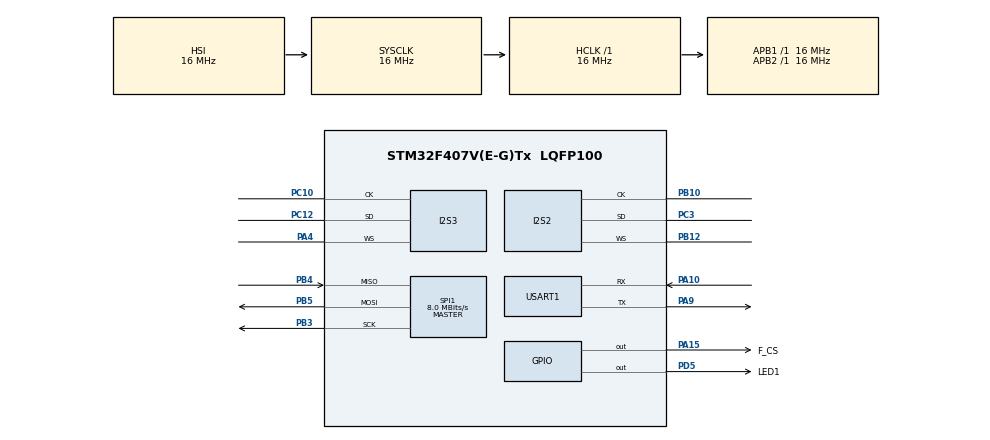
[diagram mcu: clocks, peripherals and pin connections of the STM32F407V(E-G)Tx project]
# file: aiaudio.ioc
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Dma.Request0=SPI2_RX
Dma.Request1=SPI3_TX
Dma.SPI2_RX.0.Direction=DMA_PERIPH_TO_MEMORY
Dma.SPI2_RX.0.FIFOMode=DMA_FIFOMODE_DISABLE
Dma.SPI2_RX.0.Instance=DMA1_Stream3
Dma.SPI2_RX.0.MemDataAlignment=DMA_MDATAALIGN_WORD
Dma.SPI2_RX.0.MemInc=DMA_MINC_ENABLE
Dma.SPI2_RX.0.Mode=DMA_CIRCULAR
Dma.SPI2_RX.0.PeriphDataAlignment=DMA_PDATAALIGN_WORD
Dma.SPI2_RX.0.PeriphInc=DMA_PINC_DISABLE
Dma.SPI2_RX.0.Priority=DMA_PRIORITY_LOW
Dma.SPI3_TX.1.Direction=DMA_MEMORY_TO_PERIPH
Dma.SPI3_TX.1.FIFOMode=DMA_FIFOMODE_DISABLE
Dma.SPI3_TX.1.Instance=DMA1_Stream5
Dma.SPI3_TX.1.MemDataAlignment=DMA_MDATAALIGN_HALFWORD
Dma.SPI3_TX.1.MemInc=DMA_MINC_ENABLE
Dma.SPI3_TX.1.Mode=DMA_CIRCULAR
Dma.SPI3_TX.1.PeriphDataAlignment=DMA_PDATAALIGN_HALFWORD
Dma.SPI3_TX.1.PeriphInc=DMA_PINC_DISABLE
Dma.SPI3_TX.1.Priority=DMA_PRIORITY_LOW
FREERTOS.Tasks01=defaultTask,24,128,StartDefaultTask,Default,NULL,Dynamic,NULL,NULL
I2S2.AudioFreq=I2S_AUDIOFREQ_16K
I2S2.DataFormat=I2S_DATAFORMAT_24B
I2S2.ErrorAudioFreq=0.0 %
I2S2.FullDuplexMode=I2S_FULLDUPLEXMODE_DISABLE
I2S2.Instance=SPI$Index
I2S2.Mode=I2S_MODE_MASTER_RX
I2S2.RealAudioFreq=16.0 KHz
I2S2.VirtualMode=I2S_MODE_MASTER
I2S3.AudioFreq=I2S_AUDIOFREQ_16K
I2S3.ErrorAudioFreq=0.0 %
I2S3.FullDuplexMode=I2S_FULLDUPLEXMODE_DISABLE
I2S3.Instance=SPI$Index
I2S3.RealAudioFreq=16.0 KHz
I2S3.VirtualMode=I2S_MODE_MASTER
Mcu.Family=STM32F4
Mcu.Name=STM32F407V(E-G)Tx
Mcu.Package=LQFP100
NVIC.DMA1_Stream3_IRQn=true\:5\:0\:false\:false\:true\:true\:false\:true\:true
NVIC.DMA1_Stream5_IRQn=true\:5\:0\:false\:false\:true\:true\:false\:true\:true
NVIC.PriorityGroup=NVIC_PRIORITYGROUP_4
NVIC.TIM6_DAC_IRQn=true\:15\:0\:false\:false\:true\:false\:false\:true\:true
NVIC.TimeBase=TIM6_DAC_IRQn
NVIC.TimeBaseIP=TIM6
NVIC.USART1_IRQn=true\:5\:0\:false\:false\:true\:true\:true\:true\:true
PA10.Mode=Asynchronous
PA10.Signal=USART1_RX
PA13.Mode=Serial_Wire
PA13.Signal=SYS_JTMS-SWDIO
PA14.Mode=Serial_Wire
PA14.Signal=SYS_JTCK-SWCLK
PA15.GPIO_Label=F_CS
PA15.GPIO_PuPd=GPIO_PULLUP
PA15.GPIO_Speed=GPIO_SPEED_FREQ_HIGH
PA15.PinState=GPIO_PIN_SET
PA15.Signal=GPIO_Output
PA4.Mode=Half_Duplex_Master
PA4.Signal=I2S3_WS
PA9.Mode=Asynchronous
PA9.Signal=USART1_TX
PB10.Mode=Half_Duplex_Master
PB10.Signal=I2S2_CK
PB12.Mode=Half_Duplex_Master
PB12.Signal=I2S2_WS
PB3.Mode=Full_Duplex_Master
PB3.Signal=SPI1_SCK
PB4.Mode=Full_Duplex_Master
PB4.Signal=SPI1_MISO
PB5.Mode=Full_Duplex_Master
PB5.Signal=SPI1_MOSI
PC10.Mode=Half_Duplex_Master
PC10.Signal=I2S3_CK
PC12.Mode=Half_Duplex_Master
PC12.Signal=I2S3_SD
PC3.Mode=Half_Duplex_Master
PC3.Signal=I2S2_SD
PD5.GPIO_Label=LED1
PD5.GPIO_ModeDefaultOutputPP=GPIO_MODE_OUTPUT_PP
PD5.GPIO_PuPd=GPIO_NOPULL
PD5.GPIO_Speed=GPIO_SPEED_FREQ_LOW
PD5.Signal=GPIO_Output
PH0-OSC_IN.Mode=HSE-External-Oscillator
PH0-OSC_IN.Signal=RCC_OSC_IN
PH1-OSC_OUT.Mode=HSE-External-Oscillator
PH1-OSC_OUT.Signal=RCC_OSC_OUT
ProjectManager.HeapSize=0x800
ProjectManager.StackSize=0x800
ProjectManager.TargetToolchain=CMake
RCC.AHBFreq_Value=16000000
RCC.APB1Freq_Value=16000000
RCC.APB2Freq_Value=16000000
RCC.CortexFreq_Value=16000000
RCC.HSE_VALUE=25000000
RCC.HSI_VALUE=16000000
RCC.LSE_VALUE=32768
RCC.PLLI2SN=256
RCC.SYSCLKFreq_VALUE=16000000
RCC.VCOOutputFreq_Value=192000000
SPI1.BaudRatePrescaler=SPI_BAUDRATEPRESCALER_2
SPI1.CalculateBaudRate=8.0 MBits/s
SPI1.Direction=SPI_DIRECTION_2LINES
SPI1.Mode=SPI_MODE_MASTER
SPI1.VirtualType=VM_MASTER
STMicroelectronics.X-CUBE-AI.10.2.0.ActivationBufferSizeList=28064
STMicroelectronics.X-CUBE-AI.10.2.0.ActivationBuffers=pool0
STMicroelectronics.X-CUBE-AI.10.2.0.ActivationNames=pool0
STMicroelectronics.X-CUBE-AI.10.2.0.ActivationSizes=AI_NETWORK_DATA_ACTIVATION_1_SIZE
STMicroelectronics.X-CUBE-AI.10.2.0.HeapSize=0x800
STMicroelectronics.X-CUBE-AI.10.2.0.InternalRamActivationBufferMaxSize=AI_NETWORK_DATA_ACTIVATIONS_SIZE
STMicroelectronics.X-CUBE-AI.10.2.0.LatestDirectoryUsed-1b98d699fb50468fda8fa6251d4f553b1e1db3022f8b898b0390f7f6f4bbc93a=E\:\\workspace\\projects\\embedded\\stm32-ai-assistant\\model
STMicroelectronics.X-CUBE-AI.10.2.0.MaximumNumberOfInputLayer=1
STMicroelectronics.X-CUBE-AI.10.2.0.MaximumNumberOfOutputLayer=1
STMicroelectronics.X-CUBE-AI.10.2.0.MaximumSizeOfInputLayer=1
STMicroelectronics.X-CUBE-AI.10.2.0.MaximumSizeOfOutputLayer=1
STMicroelectronics.X-CUBE-AI.10.2.0.ModelActualCompression-1b98d699fb50468fda8fa6251d4f553b1e1db3022f8b898b0390f7f6f4bbc93a=0.0
STMicroelectronics.X-CUBE-AI.10.2.0.ModelCompression-1b98d699fb50468fda8fa6251d4f553b1e1db3022f8b898b0390f7f6f4bbc93a=None
STMicroelectronics.X-CUBE-AI.10.2.0.ModelFlashOccupation-1b98d699fb50468fda8fa6251d4f553b1e1db3022f8b898b0390f7f6f4bbc93a=113956
STMicroelectronics.X-CUBE-AI.10.2.0.ModelHashList=1b98d699fb50468fda8fa6251d4f553b1e1db3022f8b898b0390f7f6f4bbc93a
STMicroelectronics.X-CUBE-AI.10.2.0.ModelKind-1b98d699fb50468fda8fa6251d4f553b1e1db3022f8b898b0390f7f6f4bbc93a=ONNX
STMicroelectronics.X-CUBE-AI.10.2.0.ModelMacc-1b98d699fb50468fda8fa6251d4f553b1e1db3022f8b898b0390f7f6f4bbc93a=758
STMicroelectronics.X-CUBE-AI.10.2.0.ModelName-1b98d699fb50468fda8fa6251d4f553b1e1db3022f8b898b0390f7f6f4bbc93a=network
STMicroelectronics.X-CUBE-AI.10.2.0.ModelNameList=network
STMicroelectronics.X-CUBE-AI.10.2.0.ModelRamOccupation-1b98d699fb50468fda8fa6251d4f553b1e1db3022f8b898b0390f7f6f4bbc93a=28064
STMicroelectronics.X-CUBE-AI.10.2.0.ModelStructureFile-1b98d699fb50468fda8fa6251d4f553b1e1db3022f8b898b0390f7f6f4bbc93a=E\:\\workspace\\projects\\embedded\\stm32-ai-assistant\\model\\avg_30.onnx
STMicroelectronics.X-CUBE-AI.10.2.0.ModelType-1b98d699fb50468fda8fa6251d4f553b1e1db3022f8b898b0390f7f6f4bbc93a=STM32Cube.AI MCU runtime
STMicroelectronics.X-CUBE-AI.10.2.0.ReadyForCodeGeneration=true
STMicroelectronics.X-CUBE-AI.10.2.0.StackSize=0x800
STMicroelectronics.X-CUBE-AI.10.2.0.WorkingBufferStartAddrList=0xFFFFFFFF
STMicroelectronics.X-CUBE-AI.10.2.0.XAaCUBEAaAICcArtificialOoIntelligenceJjCore=true
STMicroelectronics.X-CUBE-AI.10.2.0.copyWeightToRam=false
STMicroelectronics.X-CUBE-AI.10.2.0.copyWeightToRam-1b98d699fb50468fda8fa6251d4f553b1e1db3022f8b898b0390f7f6f4bbc93a=false
STMicroelectronics.X-CUBE-AI.10.2.0.customLayerConfigEnabled=false
STMicroelectronics.X-CUBE-AI.10.2.0.customLayerConfigEnabled-1b98d699fb50468fda8fa6251d4f553b1e1db3022f8b898b0390f7f6f4bbc93a=false
STMicroelectronics.X-CUBE-AI.10.2.0.noOnnxIoTranspose=false
STMicroelectronics.X-CUBE-AI.10.2.0.noOnnxIoTranspose-1b98d699fb50468fda8fa6251d4f553b1e1db3022f8b898b0390f7f6f4bbc93a=false
STMicroelectronics.X-CUBE-AI.10.2.0.useInputAllocation=true
STMicroelectronics.X-CUBE-AI.10.2.0.useInputAllocation-1b98d699fb50468fda8fa6251d4f553b1e1db3022f8b898b0390f7f6f4bbc93a=true
STMicroelectronics.X-CUBE-AI.10.2.0.useOutputAllocation=true
STMicroelectronics.X-CUBE-AI.10.2.0.useOutputAllocation-1b98d699fb50468fda8fa6251d4f553b1e1db3022f8b898b0390f7f6f4bbc93a=true
STMicroelectronics.X-CUBE-ALGOBUILD.1.4.0.LibraryCcDSPOoLibraryJjDSPOoLibrary=true
USART1.VirtualMode=VM_ASYNC
VP_FREERTOS_VS_CMSIS_V2.Mode=CMSIS_V2
VP_STMicroelectronics.X-CUBE-AI_VS_ArtificialOoIntelligenceJjXAaCUBEAaAI_10.2.0.Mode=ArtificialOoIntelligenceJjXAaCUBEAaAI
VP_STMicroelectronics.X-CUBE-ALGOBUILD_VS_DSPOoLibraryJjLibrary_1.4.0_1.4.0.Mode=DSPOoLibraryJjLibrary
VP_SYS_VS_tim6.Mode=TIM6
board=custom

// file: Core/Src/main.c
/* USER CODE BEGIN Header */
/**
  ******************************************************************************
  * @file           : main.c
  * @brief          : Main program body
  ******************************************************************************
  * @attention
  *
  * Copyright (c) 2026 STMicroelectronics.
  * All rights reserved.
  *
  * This software is licensed under terms that can be found in the LICENSE file
  * in the root directory of this software component.
  * If no LICENSE file comes with this software, it is provided AS-IS.
  *
  ******************************************************************************
  */
/* USER CODE END Header */
#include "main.h"
#include "cmsis_os.h"
#include "dma.h"
#include "i2s.h"
#include "spi.h"
#include "usart.h"
#include "gpio.h"

void SystemClock_Config(void);
void PeriphCommonClock_Config(void);
void MX_FREERTOS_Init(void);

int main(void)
{

  /* MCU Configuration--------------------------------------------------------*/

  /* Reset of all peripherals, Initializes the Flash interface and the Systick. */
  HAL_Init();

  /* Configure the system clock */
  SystemClock_Config();

  /* Configure the peripherals common clocks */
  PeriphCommonClock_Config();

  /* Initialize all configured peripherals */
  MX_GPIO_Init();
  MX_DMA_Init();
  MX_I2S2_Init();
  MX_I2S3_Init();
  MX_USART1_UART_Init();
  MX_SPI1_Init();

  /* Init scheduler */
  osKernelInitialize();  /* Call init function for freertos objects (in cmsis_os2.c) */
  MX_FREERTOS_Init();

  /* Start scheduler */
  osKernelStart();

  /* We should never get here as control is now taken by the scheduler */

  /* Infinite loop */
  while (1)
  {

  }
}

void SystemClock_Config(void)
{
  RCC_OscInitTypeDef RCC_OscInitStruct = {0};
  RCC_ClkInitTypeDef RCC_ClkInitStruct = {0};

  /** Macro to configure the PLL multiplication factor
  */
  __HAL_RCC_PLL_PLLM_CONFIG(16);

  /** Macro to configure the PLL clock source
  */
  __HAL_RCC_PLL_PLLSOURCE_CONFIG(RCC_PLLSOURCE_HSI);

  /** Configure the main internal regulator output voltage
  */
  __HAL_RCC_PWR_CLK_ENABLE();
  __HAL_PWR_VOLTAGESCALING_CONFIG(PWR_REGULATOR_VOLTAGE_SCALE1);

  /** Initializes the RCC Oscillators according to the specified parameters
  * in the RCC_OscInitTypeDef structure.
  */
  RCC_OscInitStruct.OscillatorType = RCC_OSCILLATORTYPE_HSI;
  RCC_OscInitStruct.HSIState = RCC_HSI_ON;
  RCC_OscInitStruct.HSICalibrationValue = RCC_HSICALIBRATION_DEFAULT;
  RCC_OscInitStruct.PLL.PLLState = RCC_PLL_NONE;
  RCC_OscInitStruct.PLL.PLLSource = RCC_PLLSOURCE_HSI;
  if (HAL_RCC_OscConfig(&RCC_OscInitStruct) != HAL_OK)
  {
    Error_Handler();
  }

  /** Initializes the CPU, AHB and APB buses clocks
  */
  RCC_ClkInitStruct.ClockType = RCC_CLOCKTYPE_HCLK|RCC_CLOCKTYPE_SYSCLK
                              |RCC_CLOCKTYPE_PCLK1|RCC_CLOCKTYPE_PCLK2;
  RCC_ClkInitStruct.SYSCLKSource = RCC_SYSCLKSOURCE_HSI;
  RCC_ClkInitStruct.AHBCLKDivider = RCC_SYSCLK_DIV1;
  RCC_ClkInitStruct.APB1CLKDivider = RCC_HCLK_DIV1;
  RCC_ClkInitStruct.APB2CLKDivider = RCC_HCLK_DIV1;

  if (HAL_RCC_ClockConfig(&RCC_ClkInitStruct, FLASH_LATENCY_0) != HAL_OK)
  {
    Error_Handler();
  }
}

void PeriphCommonClock_Config(void)
{
  RCC_PeriphCLKInitTypeDef PeriphClkInitStruct = {0};

  /** Initializes the peripherals clock
  */
  PeriphClkInitStruct.PeriphClockSelection = RCC_PERIPHCLK_I2S;
  PeriphClkInitStruct.PLLI2S.PLLI2SN = 256;
  PeriphClkInitStruct.PLLI2S.PLLI2SR = 2;
  if (HAL_RCCEx_PeriphCLKConfig(&PeriphClkInitStruct) != HAL_OK)
  {
    Error_Handler();
  }
}

void HAL_TIM_PeriodElapsedCallback(TIM_HandleTypeDef *htim)
{
  if (htim->Instance == TIM6)
  {
    HAL_IncTick();
  }
}

void Error_Handler(void)
{
  __disable_irq();
  while (1)
  {
  }
}

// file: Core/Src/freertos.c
/* USER CODE BEGIN Header */
/**
  ******************************************************************************
  * File Name          : freertos.c
  * Description        : Code for freertos applications
  ******************************************************************************
  * @attention
  *
  * Copyright (c) 2026 STMicroelectronics.
  * All rights reserved.
  *
  * This software is licensed under terms that can be found in the LICENSE file
  * in the root directory of this software component.
  * If no LICENSE file comes with this software, it is provided AS-IS.
  *
  ******************************************************************************
  */
/* USER CODE END Header */

#include "FreeRTOS.h"
#include "task.h"
#include "main.h"
#include "cmsis_os.h"

/* USER CODE BEGIN Includes */
#include "user_TasksInit.h"
/* USER CODE END Includes */

/* Definitions for defaultTask */
osThreadId_t defaultTaskHandle;
const osThreadAttr_t defaultTask_attributes = {
  .name = "defaultTask",
  .stack_size = 128 * 4,
  .priority = (osPriority_t) osPriorityNormal,
};

void StartDefaultTask(void *argument);

void MX_FREERTOS_Init(void); /* (MISRA C 2004 rule 8.1) */

void MX_FREERTOS_Init(void) {

  /* Create the thread(s) */
  /* creation of defaultTask */
  defaultTaskHandle = osThreadNew(StartDefaultTask, NULL, &defaultTask_attributes);

  /* USER CODE BEGIN RTOS_THREADS */
  User_Tasks_Init();
  /* USER CODE END RTOS_THREADS */

}

void StartDefaultTask(void *argument)
{
  for(;;)
  {
    osDelay(1);
  }
}
